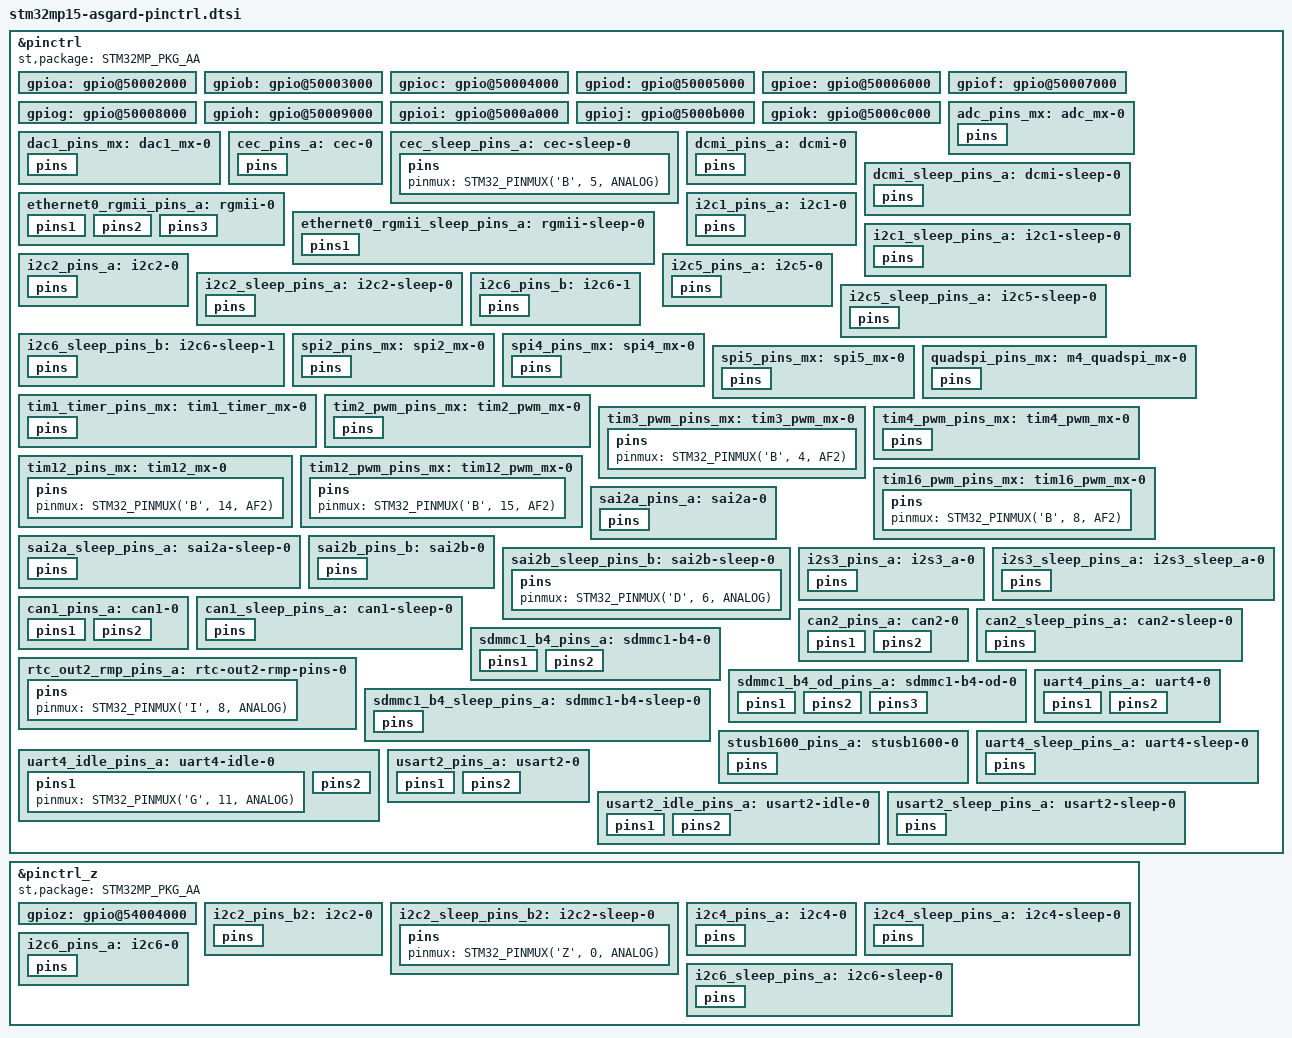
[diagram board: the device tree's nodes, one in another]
// SPDX-License-Identifier: (GPL-2.0+ OR BSD-3-Clause)
/*
 * Copyright (C) STMicroelectronics 2017 - All Rights Reserved
 * Author: Ludovic Barre <ludovic.barre@st.com> for STMicroelectronics.
 */
#include <dt-bindings/pinctrl/stm32-pinfunc.h>

&pinctrl {
	st,package = <STM32MP_PKG_AA>;

	gpioa: gpio@50002000 {
		status = "okay";
		ngpios = <16>;
		gpio-ranges = <&pinctrl 0 0 16>;
	};

	gpiob: gpio@50003000 {
		status = "okay";
		ngpios = <16>;
		gpio-ranges = <&pinctrl 0 16 16>;
	};

	gpioc: gpio@50004000 {
		status = "okay";
		ngpios = <16>;
		gpio-ranges = <&pinctrl 0 32 16>;
	};

	gpiod: gpio@50005000 {
		status = "okay";
		ngpios = <16>;
		gpio-ranges = <&pinctrl 0 48 16>;
	};

	gpioe: gpio@50006000 {
		status = "okay";
		ngpios = <16>;
		gpio-ranges = <&pinctrl 0 64 16>;
	};

	gpiof: gpio@50007000 {
		status = "okay";
		ngpios = <16>;
		gpio-ranges = <&pinctrl 0 80 16>;
	};

	gpiog: gpio@50008000 {
		status = "okay";
		ngpios = <16>;
		gpio-ranges = <&pinctrl 0 96 16>;
	};

	gpioh: gpio@50009000 {
		status = "okay";
		ngpios = <16>;
		gpio-ranges = <&pinctrl 0 112 16>;
	};

	gpioi: gpio@5000a000 {
		status = "okay";
		ngpios = <16>;
		gpio-ranges = <&pinctrl 0 128 16>;
	};

	gpioj: gpio@5000b000 {
		status = "okay";
		ngpios = <16>;
		gpio-ranges = <&pinctrl 0 144 16>;
	};

	gpiok: gpio@5000c000 {
		status = "okay";
		ngpios = <8>;
		gpio-ranges = <&pinctrl 0 160 8>;
	};
	
	adc_pins_mx: adc_mx-0 {
		pins {
			pinmux = <STM32_PINMUX('A', 3, ANALOG)>, /* ADC1_INP15 */
				 <STM32_PINMUX('F', 11, ANALOG)>, /* ADC1_INP2 */
				 <STM32_PINMUX('F', 12, ANALOG)>; /* ADC1_INP6 */
		};
	};

	dac1_pins_mx: dac1_mx-0 {
		pins {
			pinmux = <STM32_PINMUX('A', 4, ANALOG)>, /* DAC1_OUT1 */
			         <STM32_PINMUX('A', 5, ANALOG)>; /* DAC1_OUT2 */
		};
	};

	cec_pins_a: cec-0 {
		pins {
			pinmux = <STM32_PINMUX('B', 5, AF5)>;
			bias-disable;
			drive-open-drain;
			slew-rate = <0>;
		};
	};

	cec_sleep_pins_a: cec-sleep-0 {
		pins {
			pinmux = <STM32_PINMUX('B', 5, ANALOG)>; /* HDMI_CEC */
		};
	};
	
	dcmi_pins_a: dcmi-0 {
		pins {
			pinmux = <STM32_PINMUX('H', 8,  AF13)>,/* DCMI_HSYNC */
				 <STM32_PINMUX('I', 5,  AF13)>,/* DCMI_VSYNC */
				 <STM32_PINMUX('A', 6,  AF13)>,/* DCMI_PIXCLK */
				 <STM32_PINMUX('H', 9,  AF13)>,/* DCMI_D0 */
				 <STM32_PINMUX('H', 10, AF13)>,/* DCMI_D1 */
				 <STM32_PINMUX('H', 11, AF13)>,/* DCMI_D2 */
				 <STM32_PINMUX('H', 12, AF13)>,/* DCMI_D3 */
				 <STM32_PINMUX('H', 14, AF13)>,/* DCMI_D4 */
				 <STM32_PINMUX('I', 4,  AF13)>,/* DCMI_D5 */
				 <STM32_PINMUX('E', 13,  AF13)>,/* DCMI_D6 */
				 <STM32_PINMUX('E', 6,  AF13)>,/* DCMI_D7 */
				 <STM32_PINMUX('I', 1,  AF13)>,/* DCMI_D8 */
				 <STM32_PINMUX('H', 6,  AF13)>,/* DCMI_D9 */
				 <STM32_PINMUX('I', 3,  AF13)>,/* DCMI_D10 */
				 <STM32_PINMUX('H', 15, AF13)>;/* DCMI_D11 */
			bias-disable;
		};
	};

	dcmi_sleep_pins_a: dcmi-sleep-0 {
		pins {
			pinmux = <STM32_PINMUX('H', 8,  ANALOG)>,/* DCMI_HSYNC */
				 <STM32_PINMUX('I', 5,  ANALOG)>,/* DCMI_VSYNC */
				 <STM32_PINMUX('A', 6,  ANALOG)>,/* DCMI_PIXCLK */
				 <STM32_PINMUX('H', 9,  ANALOG)>,/* DCMI_D0 */
				 <STM32_PINMUX('H', 10, ANALOG)>,/* DCMI_D1 */
				 <STM32_PINMUX('H', 11, ANALOG)>,/* DCMI_D2 */
				 <STM32_PINMUX('H', 12, ANALOG)>,/* DCMI_D3 */
				 <STM32_PINMUX('H', 14, ANALOG)>,/* DCMI_D4 */
				 <STM32_PINMUX('I', 4,  ANALOG)>,/* DCMI_D5 */
				 <STM32_PINMUX('E', 13,  ANALOG)>,/* DCMI_D6 */
				 <STM32_PINMUX('E', 6,  ANALOG)>,/* DCMI_D7 */
				 <STM32_PINMUX('I', 1,  ANALOG)>,/* DCMI_D8 */
				 <STM32_PINMUX('H', 6,  ANALOG)>,/* DCMI_D9 */
				 <STM32_PINMUX('I', 3,  ANALOG)>,/* DCMI_D10 */
				 <STM32_PINMUX('H', 15, ANALOG)>;/* DCMI_D11 */
		};
	};

	ethernet0_rgmii_pins_a: rgmii-0 {
		pins1 {
			pinmux = <STM32_PINMUX('G', 5, AF11)>, /* ETH_RGMII_CLK125 */
				 <STM32_PINMUX('G', 4, AF11)>, /* ETH_RGMII_GTX_CLK */
				 <STM32_PINMUX('G', 13, AF11)>, /* ETH_RGMII_TXD0 */
				 <STM32_PINMUX('G', 14, AF11)>, /* ETH_RGMII_TXD1 */
				 <STM32_PINMUX('C', 2, AF11)>, /* ETH_RGMII_TXD2 */
				 <STM32_PINMUX('E', 2, AF11)>, /* ETH_RGMII_TXD3 */
				 <STM32_PINMUX('B', 11, AF11)>, /* ETH_RGMII_TX_CTL */
				 <STM32_PINMUX('C', 1, AF11)>; /* ETH_MDC */
			bias-disable;
			drive-push-pull;
			slew-rate = <2>;
		};
		pins2 {
			pinmux = <STM32_PINMUX('A', 2, AF11)>; /* ETH_MDIO */
			bias-disable;
			drive-push-pull;
			slew-rate = <0>;
		};
		pins3 {
			pinmux = <STM32_PINMUX('C', 4, AF11)>, /* ETH_RGMII_RXD0 */
				 <STM32_PINMUX('C', 5, AF11)>, /* ETH_RGMII_RXD1 */
				 <STM32_PINMUX('B', 0, AF11)>, /* ETH_RGMII_RXD2 */
				 <STM32_PINMUX('B', 1, AF11)>, /* ETH_RGMII_RXD3 */
				 <STM32_PINMUX('A', 1, AF11)>, /* ETH_RGMII_RX_CLK */
				 <STM32_PINMUX('A', 7, AF11)>; /* ETH_RGMII_RX_CTL */
			bias-disable;
		};
	};

	ethernet0_rgmii_sleep_pins_a: rgmii-sleep-0 {
		pins1 {
			pinmux = <STM32_PINMUX('G', 5, ANALOG)>, /* ETH_RGMII_CLK125 */
				 <STM32_PINMUX('G', 4, ANALOG)>, /* ETH_RGMII_GTX_CLK */
				 <STM32_PINMUX('G', 13, ANALOG)>, /* ETH_RGMII_TXD0 */
				 <STM32_PINMUX('G', 14, ANALOG)>, /* ETH_RGMII_TXD1 */
				 <STM32_PINMUX('C', 2, ANALOG)>, /* ETH_RGMII_TXD2 */
				 <STM32_PINMUX('E', 2, ANALOG)>, /* ETH_RGMII_TXD3 */
				 <STM32_PINMUX('B', 11, ANALOG)>, /* ETH_RGMII_TX_CTL */
				 <STM32_PINMUX('A', 2, ANALOG)>, /* ETH_MDIO */
				 <STM32_PINMUX('C', 1, ANALOG)>, /* ETH_MDC */
				 <STM32_PINMUX('C', 4, ANALOG)>, /* ETH_RGMII_RXD0 */
				 <STM32_PINMUX('C', 5, ANALOG)>, /* ETH_RGMII_RXD1 */
				 <STM32_PINMUX('B', 0, ANALOG)>, /* ETH_RGMII_RXD2 */
				 <STM32_PINMUX('B', 1, ANALOG)>, /* ETH_RGMII_RXD3 */
				 <STM32_PINMUX('A', 1, ANALOG)>, /* ETH_RGMII_RX_CLK */
				 <STM32_PINMUX('A', 7, ANALOG)>; /* ETH_RGMII_RX_CTL */
		};
	};

	i2c1_pins_a: i2c1-0 {
		pins {
			pinmux = <STM32_PINMUX('F', 14, AF5)>, /* I2C1_SCL */
				 <STM32_PINMUX('F', 15, AF5)>; /* I2C1_SDA */
			bias-disable;
			drive-open-drain;
			slew-rate = <0>;
		};
	};

	i2c1_sleep_pins_a: i2c1-sleep-0 {
		pins {
			pinmux = <STM32_PINMUX('F', 14, ANALOG)>, /* I2C1_SCL */
				 <STM32_PINMUX('F', 15, ANALOG)>; /* I2C1_SDA */
		};
	};

	i2c2_pins_a: i2c2-0 {
		pins {
			pinmux = <STM32_PINMUX('F', 1, AF4)>, /* I2C2_SCL */
				 <STM32_PINMUX('G', 15, AF4)>; /* I2C2_SDA */
			bias-disable;
			drive-open-drain;
			slew-rate = <0>;
		};
	};

	i2c2_sleep_pins_a: i2c2-sleep-0 {
		pins {
			pinmux = <STM32_PINMUX('F', 1, ANALOG)>, /* I2C2_SCL */
				 <STM32_PINMUX('G', 15, ANALOG)>; /* I2C2_SDA */
		};
	};

	i2c5_pins_a: i2c5-0 {
		pins {
			pinmux = <STM32_PINMUX('A', 11, AF4)>, /* I2C5_SCL */
				 <STM32_PINMUX('A', 12, AF4)>; /* I2C5_SDA */
			bias-disable;
			drive-open-drain;
			slew-rate = <0>;
		};
	};

	i2c5_sleep_pins_a: i2c5-sleep-0 {
		pins {
			pinmux = <STM32_PINMUX('A', 11, ANALOG)>, /* I2C5_SCL */
				 <STM32_PINMUX('A', 12, ANALOG)>; /* I2C5_SDA */

		};
	};

	i2c6_pins_b: i2c6-1 {
		pins {
			pinmux = <STM32_PINMUX('D', 1, AF2)>, /* I2C6_SCL */
				 <STM32_PINMUX('D', 0, AF2)>; /* I2C6_SDA */
			bias-disable;
			drive-open-drain;
			slew-rate = <0>;
		};
	};

	i2c6_sleep_pins_b: i2c6-sleep-1 {
		pins {
			pinmux = <STM32_PINMUX('D', 1, ANALOG)>, /* I2C6_SCL */
				 <STM32_PINMUX('D', 0, ANALOG)>; /* I2C6_SDA */
		};
	};

	spi2_pins_mx: spi2_mx-0 {
		pins {
			pinmux = <STM32_PINMUX('A', 9, AF5)>, 	/* SPI2_SCK */
					 <STM32_PINMUX('C', 3, AF5)>, /* SPI2_MOSI */
					 <STM32_PINMUX('I', 0, AF5)>, /* SPI2_NSS */
					 <STM32_PINMUX('I', 2, AF5)>; /* SPI2_MISO */
		};
	};

	spi4_pins_mx: spi4_mx-0 {
		pins {
			pinmux = <STM32_PINMUX('E', 5, AF5)>, /* SPI4_MISO */
					 <STM32_PINMUX('E', 12, AF5)>, /* SPI4_SCK */
					 <STM32_PINMUX('E', 14, AF5)>; /* SPI4_MOSI */
		};
	};

	spi5_pins_mx: spi5_mx-0 {
		pins {
			pinmux = <STM32_PINMUX('H', 5, AF5)>, /* SPI5_NSS */
					 <STM32_PINMUX('H', 6, AF5)>, /* SPI5_SCK */
					 <STM32_PINMUX('J', 10, AF5)>, /* SPI5_MOSI */
					 <STM32_PINMUX('J', 11, AF5)>; /* SPI5_MISO */
		};
	};
	
	quadspi_pins_mx: m4_quadspi_mx-0 {
		pins {
			pinmux = <STM32_PINMUX('B', 6, AF10)>, /* QUADSPI_BK1_NCS */
				 <STM32_PINMUX('C', 0, AF10)>, /* QUADSPI_BK2_NCS */
				 <STM32_PINMUX('F', 6, AF9)>, /* QUADSPI_BK1_IO3 */
				 <STM32_PINMUX('F', 7, AF9)>, /* QUADSPI_BK1_IO2 */
				 <STM32_PINMUX('F', 8, AF10)>, /* QUADSPI_BK1_IO0 */
				 <STM32_PINMUX('F', 9, AF10)>, /* QUADSPI_BK1_IO1 */
				 <STM32_PINMUX('F', 10, AF9)>, /* QUADSPI_CLK */
				 <STM32_PINMUX('G', 7, AF11)>, /* QUADSPI_BK2_IO3 */
				 <STM32_PINMUX('G', 10, AF11)>, /* QUADSPI_BK2_IO2 */
				 <STM32_PINMUX('H', 2, AF9)>, /* QUADSPI_BK2_IO0 */
				 <STM32_PINMUX('H', 3, AF9)>; /* QUADSPI_BK2_IO1 */
		};
	};

	tim1_timer_pins_mx: tim1_timer_mx-0 {
		pins {
			pinmux = <STM32_PINMUX('A', 8, AF1)>, /* TIM1_CH1 */
					 <STM32_PINMUX('E', 11, AF2)>; /* TIM1_CH2 */
		};
	};

	tim2_pwm_pins_mx: tim2_pwm_mx-0 {
		pins {
			pinmux = <STM32_PINMUX('B', 3, AF2)>, /* TIM2_CH2 */
					 <STM32_PINMUX('B', 10, AF2)>; /* TIM2_CH3 */
		};
	};

	tim3_pwm_pins_mx: tim3_pwm_mx-0 {
		pins {
			pinmux = <STM32_PINMUX('B', 4, AF2)>; /* TIM3_CH1 */
		};
	};

	tim4_pwm_pins_mx: tim4_pwm_mx-0 {
		pins {
			pinmux = <STM32_PINMUX('B', 7, AF2)>, /* TIM4_CH2 */
					 <STM32_PINMUX('D', 12, AF2)>, /* TIM4_CH1 */
					 <STM32_PINMUX('D', 14, AF2)>, /* TIM4_CH3 */
					 <STM32_PINMUX('D', 15, AF2)>; /* TIM4_CH4 */
		};
	};
	
	tim12_pins_mx: tim12_mx-0 {
		pins {
			pinmux = <STM32_PINMUX('B', 14, AF2)>; /* TIM12_CH1 */
		};
	};

	tim12_pwm_pins_mx: tim12_pwm_mx-0 {
		pins {
			pinmux = <STM32_PINMUX('B', 15, AF2)>; /* TIM12_CH2 */
		};
	};

	tim16_pwm_pins_mx: tim16_pwm_mx-0 {
		pins {
			pinmux = <STM32_PINMUX('B', 8, AF2)>; /* TIM16_CH1 */
		};
	};

	sai2a_pins_a: sai2a-0 {
		pins {
			pinmux = <STM32_PINMUX('E', 0, AF10)>, /* SAI2_SCK_A */
				 <STM32_PINMUX('D', 10, AF10)>, /* SAI2_SD_A */
				 <STM32_PINMUX('A', 15, AF10)>, /* SAI2_FS_A */
				 <STM32_PINMUX('D', 13, AF10)>; /* SAI2_MCLK_A */
			slew-rate = <0>;
			drive-push-pull;
			bias-disable;
		};
	};

	sai2a_sleep_pins_a: sai2a-sleep-0 {
		pins {
			pinmux = <STM32_PINMUX('E', 0, ANALOG)>, /* SAI2_SCK_A */
				 <STM32_PINMUX('D', 10, ANALOG)>, /* SAI2_SD_A */
				 <STM32_PINMUX('A', 15, ANALOG)>, /* SAI2_FS_A */
				 <STM32_PINMUX('D', 13, ANALOG)>; /* SAI2_MCLK_A */
		};
	};

	sai2b_pins_b: sai2b-0 {
		pins {
			pinmux = <STM32_PINMUX('D', 6, AF10)>; /* SAI2_SD_B */
			bias-disable;
		};
	};

	sai2b_sleep_pins_b: sai2b-sleep-0 {
		pins {
			pinmux = <STM32_PINMUX('D', 6, ANALOG)>; /* SAI2_SD_B */
		};
	};
		
	i2s3_pins_a: i2s3_a-0 {
		pins {
			pinmux = <STM32_PINMUX('A', 15, AF6)>, 	/* I2S3_WS */
				 <STM32_PINMUX('D', 6, AF5)>, 	/* I2S3_SDO */
				 <STM32_PINMUX('D', 10, AF5)>, 	/* I2S3_SDI */
				 <STM32_PINMUX('D', 13, AF6)>, 	/* I2S3_MCK */
				 <STM32_PINMUX('E', 0, AF5)>; 	/* I2S3_CK */
			bias-disable;
			drive-push-pull;
			slew-rate = <1>;
		};
	};

	i2s3_sleep_pins_a: i2s3_sleep_a-0 {
		pins {
			pinmux = <STM32_PINMUX('A', 15, ANALOG)>, 	/* I2S3_WS */
				 <STM32_PINMUX('D', 6, ANALOG)>, 	/* I2S3_SDO */
				 <STM32_PINMUX('D', 10, ANALOG)>, 	/* I2S3_SDI */
				 <STM32_PINMUX('D', 13, ANALOG)>, 	/* I2S3_MCK */
				 <STM32_PINMUX('E', 0, ANALOG)>; 	/* I2S3_CK */
		};
	};

	can1_pins_a: can1-0 {
		pins1 {
			pinmux = <STM32_PINMUX('H', 13, AF9)>; /* CAN1_TX */
			slew-rate = <1>;
			drive-push-pull;
			bias-disable;
		};
		pins2 {
			pinmux = <STM32_PINMUX('I', 9, AF9)>; /* CAN1_RX */
			bias-disable;
		};
	};

	can1_sleep_pins_a: can1-sleep-0 {
		pins {
			pinmux = <STM32_PINMUX('H', 13, ANALOG)>, /* CAN1_TX */
				 <STM32_PINMUX('I', 9, ANALOG)>; /* CAN1_RX */
		};
	};

	can2_pins_a: can2-0 {
		pins1 {
			pinmux = <STM32_PINMUX('B', 13, AF9)>; /* CAN2_TX */
			slew-rate = <1>;
			drive-push-pull;
			bias-disable;
		};
		pins2 {
			pinmux = <STM32_PINMUX('B', 5, AF9)>; /* CAN2_RX */
			bias-disable;
		};
	};

	can2_sleep_pins_a: can2-sleep-0 {
		pins {
			pinmux = <STM32_PINMUX('B', 13, ANALOG)>, /* CAN2_TX */
				 <STM32_PINMUX('B', 5, ANALOG)>; /* CAN2_RX */
		};
	};

	rtc_out2_rmp_pins_a: rtc-out2-rmp-pins-0 {
		pins {
			pinmux = <STM32_PINMUX('I', 8, ANALOG)>; /* RTC_OUT2_RMP */
		};
	};

	sdmmc1_b4_pins_a: sdmmc1-b4-0 {
		pins1 {
			pinmux = <STM32_PINMUX('C', 8, AF12)>, /* SDMMC1_D0 */
				 <STM32_PINMUX('C', 9, AF12)>, /* SDMMC1_D1 */
				 <STM32_PINMUX('C', 10, AF12)>, /* SDMMC1_D2 */
				 <STM32_PINMUX('C', 11, AF12)>, /* SDMMC1_D3 */
				 <STM32_PINMUX('D', 2, AF12)>; /* SDMMC1_CMD */
			slew-rate = <1>;
			drive-push-pull;
			bias-disable;
		};
		pins2 {
			pinmux = <STM32_PINMUX('C', 12, AF12)>; /* SDMMC1_CK */
			slew-rate = <2>;
			drive-push-pull;
			bias-disable;
		};
	};

	sdmmc1_b4_od_pins_a: sdmmc1-b4-od-0 {
		pins1 {
			pinmux = <STM32_PINMUX('C', 8, AF12)>, /* SDMMC1_D0 */
				 <STM32_PINMUX('C', 9, AF12)>, /* SDMMC1_D1 */
				 <STM32_PINMUX('C', 10, AF12)>, /* SDMMC1_D2 */
				 <STM32_PINMUX('C', 11, AF12)>; /* SDMMC1_D3 */
			slew-rate = <1>;
			drive-push-pull;
			bias-disable;
		};
		pins2 {
			pinmux = <STM32_PINMUX('C', 12, AF12)>; /* SDMMC1_CK */
			slew-rate = <2>;
			drive-push-pull;
			bias-disable;
		};
		pins3 {
			pinmux = <STM32_PINMUX('D', 2, AF12)>; /* SDMMC1_CMD */
			slew-rate = <1>;
			drive-open-drain;
			bias-disable;
		};
	};

	sdmmc1_b4_sleep_pins_a: sdmmc1-b4-sleep-0 {
		pins {
			pinmux = <STM32_PINMUX('C', 8, ANALOG)>, /* SDMMC1_D0 */
				 <STM32_PINMUX('C', 9, ANALOG)>, /* SDMMC1_D1 */
				 <STM32_PINMUX('C', 10, ANALOG)>, /* SDMMC1_D2 */
				 <STM32_PINMUX('C', 11, ANALOG)>, /* SDMMC1_D3 */
				 <STM32_PINMUX('C', 12, ANALOG)>, /* SDMMC1_CK */
				 <STM32_PINMUX('D', 2, ANALOG)>; /* SDMMC1_CMD */
		};
	};

	stusb1600_pins_a: stusb1600-0 {
		pins {
			pinmux = <STM32_PINMUX('B', 3, ANALOG)>;
			bias-pull-up;
		};
	};

	uart4_pins_a: uart4-0 {
		pins1 {
			pinmux = <STM32_PINMUX('G', 11, AF6)>; /* UART4_TX */
			bias-disable;
			drive-push-pull;
			slew-rate = <0>;
		};
		pins2 {
			pinmux = <STM32_PINMUX('B', 2, AF8)>; /* UART4_RX */
			bias-disable;
		};
	};

	uart4_idle_pins_a: uart4-idle-0 {
		   pins1 {
			 pinmux = <STM32_PINMUX('G', 11, ANALOG)>; /* UART4_TX */
		   };
		   pins2 {
			 pinmux = <STM32_PINMUX('B', 2, AF8)>; /* UART4_RX */
			 bias-disable;
		   };
	};

	uart4_sleep_pins_a: uart4-sleep-0 {
		   pins {
			pinmux = <STM32_PINMUX('G', 11, ANALOG)>, /* UART4_TX */
				 <STM32_PINMUX('B', 2, ANALOG)>; /* UART4_RX */
		    };
	};

	usart2_pins_a: usart2-0 {
		pins1 {
			/* usart2 TX and RTS pins activation for default mode */
			pinmux = <STM32_PINMUX('D', 5, AF7)>, /* usart2_TX */
				 <STM32_PINMUX('D', 4, AF8)>; /* usart2_RTS */
			bias-disable;
			drive-push-pull;
			slew-rate = <0>;
		};
		pins2 {
			/* usart2 RX and CTS_NSS pins activation for default mode */
			pinmux = <STM32_PINMUX('F', 4, AF8)>, /* usart2_RX */
			 	<STM32_PINMUX('D', 3, AF8)>; /* usart2_CTS_NSS */
			bias-disable;
		};
	};

	usart2_idle_pins_a: usart2-idle-0 {
		pins1 {
			/* usart2 TX, RTS, and CTS_NSS pins deactivation for sleep mode */
			pinmux = <STM32_PINMUX('D', 5, ANALOG)>, /* usart2_TX */
				 <STM32_PINMUX('D', 4, ANALOG)>, /* usart2_RTS */
				 <STM32_PINMUX('D', 3, ANALOG)>; /* usart2_CTS_NSS */      
		};
		pins2 {
			/* usart2_RX pin still active for wake up */
			pinmux = <STM32_PINMUX('F', 4, AF8)>; /* usart2_RX */
			bias-disable;
		};
	};

	usart2_sleep_pins_a: usart2-sleep-0 {
		pins {
			/* usart2_TX, RTS, CTS_NSS, and RX pins deactivation for sleep mode */
			pinmux = <STM32_PINMUX('D', 5, ANALOG)>, /* usart2_TX */
				 <STM32_PINMUX('D', 4, ANALOG)>, /* usart2_RTS */
				 <STM32_PINMUX('D', 3, ANALOG)>, /* usart2_CTS_NSS */
				 <STM32_PINMUX('F', 4, ANALOG)>; /* usart2_RX */
		};
	};
};

&pinctrl_z {
	st,package = <STM32MP_PKG_AA>;

	gpioz: gpio@54004000 {
		status = "okay";
		ngpios = <8>;
		gpio-ranges = <&pinctrl_z 0 400 8>;
	};
	
	i2c2_pins_b2: i2c2-0 {
		pins {
			pinmux = <STM32_PINMUX('Z', 0, AF3)>; /* I2C2_SCL */
			bias-disable;
			drive-open-drain;
			slew-rate = <0>;
		};
	};

	i2c2_sleep_pins_b2: i2c2-sleep-0 {
		pins {
			pinmux = <STM32_PINMUX('Z', 0, ANALOG)>; /* I2C2_SCL */
		};
	};

	i2c4_pins_a: i2c4-0 {
		pins {
			pinmux = <STM32_PINMUX('Z', 4, AF6)>, /* I2C4_SCL */
				 <STM32_PINMUX('Z', 5, AF6)>; /* I2C4_SDA */
			bias-disable;
			drive-open-drain;
			slew-rate = <0>;
		};
	};

	i2c4_sleep_pins_a: i2c4-sleep-0 {
		pins {
			pinmux = <STM32_PINMUX('Z', 4, ANALOG)>, /* I2C4_SCL */
				 <STM32_PINMUX('Z', 5, ANALOG)>; /* I2C4_SDA */
		};
	};

	i2c6_pins_a: i2c6-0 {
		pins {
			pinmux = <STM32_PINMUX('Z', 6, AF2)>, /* I2C6_SCL */
				 <STM32_PINMUX('Z', 7, AF2)>; /* I2C6_SDA */
			bias-disable;
			drive-open-drain;
			slew-rate = <0>;
		};
	};

	i2c6_sleep_pins_a: i2c6-sleep-0 {
		pins {
			pinmux = <STM32_PINMUX('Z', 6, ANALOG)>, /* I2C6_SCL */
				 <STM32_PINMUX('Z', 7, ANALOG)>; /* I2C6_SDA */
		};
	};
};
